# bao1x register map
Vendor: baochip; File version: 1.0
Registers are 32-bit, read-write, reset 0x0 unless marked. A register's access mark holds for its fields unless they carry their own. Offsets are from the block's base; [hi:lo] are bit positions; {n}, {i} and the like mark numbered series.

## IRQARRAY2
Base 0xE0010000
0x00 EV_SOFT — Software interrupt trigger register. ) Bits set to `1` will trigger an interrupt. Interrupts trigger on write, but the value will persist in the register, allowing software to determine if a software interrupt was triggered by reading back the register. Software is responsible for clearing the register to 0. Repeated `1` writes without clearing will still trigger an interrupt.
  [15:0] trigger
0x04 EV_EDGE_TRIGGERED — If a bit is set to 1, then the hardware trigger is edge-triggered
  [15:0] use_edge
0x08 EV_POLARITY — If a bit is set to 1, then the polarity is rising edge triggered; 0 is falling edge triggered. Bit is ignored if `edge_triggered` is 0.
  [15:0] rising
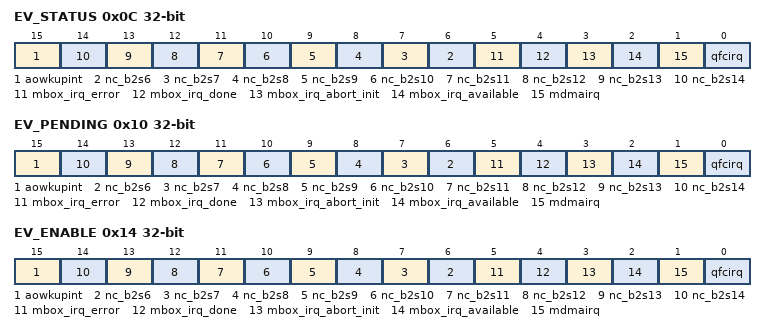
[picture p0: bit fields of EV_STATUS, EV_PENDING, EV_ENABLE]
0x0C EV_STATUS — `1` when a "aowkupint" event occurs. This event uses an `EventSourceFlex` form of triggering
  [15] aowkupint — Level of the ``aowkupint`` event
  [n] nc_b2s{n} (n=6..14) — Level of the ``nc_b2s{n}`` event
  [5] mbox_irq_error — Level of the ``mbox_irq_error`` event
  [4] mbox_irq_done — Level of the ``mbox_irq_done`` event
  [3] mbox_irq_abort_init — Level of the ``mbox_irq_abort_init`` event
  [2] mbox_irq_available — Level of the ``mbox_irq_available`` event
  [1] mdmairq — Level of the ``mdmairq`` event
  [0] qfcirq — Level of the ``qfcirq`` event
0x10 EV_PENDING — `1` when a "aowkupint" event occurs. This event uses an `EventSourceFlex` form of triggering
  [15] aowkupint — `1` when a "aowkupint" event occurs. This event uses an `EventSourceFlex` form of triggering
  [n] nc_b2s{n} (n=6..14) — `1` when a "nc_b2s{n}" event occurs. This event uses an `EventSourceFlex` form of triggering
  [5] mbox_irq_error — `1` when a "mbox_irq_error" event occurs. This event uses an `EventSourceFlex` form of triggering
  [4] mbox_irq_done — `1` when a "mbox_irq_done" event occurs. This event uses an `EventSourceFlex` form of triggering
  [3] mbox_irq_abort_init — `1` when a "mbox_irq_abort_init" event occurs. This event uses an `EventSourceFlex` form of triggering
  [2] mbox_irq_available — `1` when a "mbox_irq_available" event occurs. This event uses an `EventSourceFlex` form of triggering
  [1] mdmairq — `1` when a "mdmairq" event occurs. This event uses an `EventSourceFlex` form of triggering
  [0] qfcirq — `1` when a "qfcirq" event occurs. This event uses an `EventSourceFlex` form of triggering
0x14 EV_ENABLE — `1` when a "aowkupint" event occurs. This event uses an `EventSourceFlex` form of triggering
  [15] aowkupint — Write a ``1`` to enable the ``aowkupint`` Event
  [n] nc_b2s{n} (n=6..14) — Write a ``1`` to enable the ``nc_b2s{n}`` Event
  [5] mbox_irq_error — Write a ``1`` to enable the ``mbox_irq_error`` Event
  [4] mbox_irq_done — Write a ``1`` to enable the ``mbox_irq_done`` Event
  [3] mbox_irq_abort_init — Write a ``1`` to enable the ``mbox_irq_abort_init`` Event
  [2] mbox_irq_available — Write a ``1`` to enable the ``mbox_irq_available`` Event
  [1] mdmairq — Write a ``1`` to enable the ``mdmairq`` Event
  [0] qfcirq — Write a ``1`` to enable the ``qfcirq`` Event

## IRQARRAY3
Base 0xE0011000
0x00 EV_SOFT — Software interrupt trigger register. ) Bits set to `1` will trigger an interrupt. Interrupts trigger on write, but the value will persist in the register, allowing software to determine if a software interrupt was triggered by reading back the register. Software is responsible for clearing the register to 0. Repeated `1` writes without clearing will still trigger an interrupt.
  [15:0] trigger
0x04 EV_EDGE_TRIGGERED — If a bit is set to 1, then the hardware trigger is edge-triggered
  [15:0] use_edge
0x08 EV_POLARITY — If a bit is set to 1, then the polarity is rising edge triggered; 0 is falling edge triggered. Bit is ignored if `edge_triggered` is 0.
  [15:0] rising
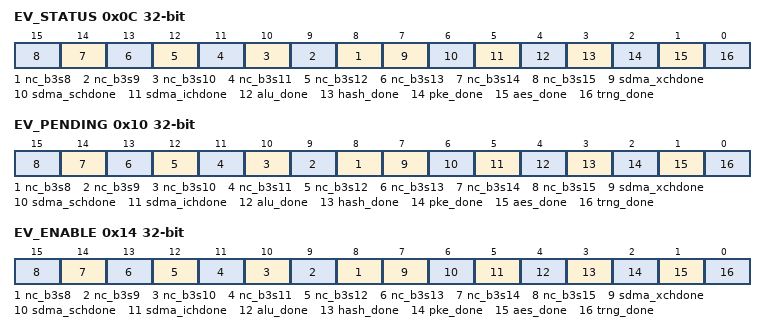
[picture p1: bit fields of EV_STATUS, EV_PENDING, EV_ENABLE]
0x0C EV_STATUS — `1` when a "nc_b3s15" event occurs. This event uses an `EventSourceFlex` form of triggering
  [n] nc_b3s{n} (n=8..15) — Level of the ``nc_b3s{n}`` event
  [7] sdma_xchdone — Level of the ``sdma_xchdone`` event
  [6] sdma_schdone — Level of the ``sdma_schdone`` event
  [5] sdma_ichdone — Level of the ``sdma_ichdone`` event
  [4] alu_done — Level of the ``alu_done`` event
  [3] hash_done — Level of the ``hash_done`` event
  [2] pke_done — Level of the ``pke_done`` event
  [1] aes_done — Level of the ``aes_done`` event
  [0] trng_done — Level of the ``trng_done`` event
0x10 EV_PENDING — `1` when a "nc_b3s15" event occurs. This event uses an `EventSourceFlex` form of triggering
  [n] nc_b3s{n} (n=8..15) — `1` when a "nc_b3s{n}" event occurs. This event uses an `EventSourceFlex` form of triggering
  [7] sdma_xchdone — `1` when a "sdma_xchdone" event occurs. This event uses an `EventSourceFlex` form of triggering
  [6] sdma_schdone — `1` when a "sdma_schdone" event occurs. This event uses an `EventSourceFlex` form of triggering
  [5] sdma_ichdone — `1` when a "sdma_ichdone" event occurs. This event uses an `EventSourceFlex` form of triggering
  [4] alu_done — `1` when a "alu_done" event occurs. This event uses an `EventSourceFlex` form of triggering
  [3] hash_done — `1` when a "hash_done" event occurs. This event uses an `EventSourceFlex` form of triggering
  [2] pke_done — `1` when a "pke_done" event occurs. This event uses an `EventSourceFlex` form of triggering
  [1] aes_done — `1` when a "aes_done" event occurs. This event uses an `EventSourceFlex` form of triggering
  [0] trng_done — `1` when a "trng_done" event occurs. This event uses an `EventSourceFlex` form of triggering
0x14 EV_ENABLE — `1` when a "nc_b3s15" event occurs. This event uses an `EventSourceFlex` form of triggering
  [n] nc_b3s{n} (n=8..15) — Write a ``1`` to enable the ``nc_b3s{n}`` Event
  [7] sdma_xchdone — Write a ``1`` to enable the ``sdma_xchdone`` Event
  [6] sdma_schdone — Write a ``1`` to enable the ``sdma_schdone`` Event
  [5] sdma_ichdone — Write a ``1`` to enable the ``sdma_ichdone`` Event
  [4] alu_done — Write a ``1`` to enable the ``alu_done`` Event
  [3] hash_done — Write a ``1`` to enable the ``hash_done`` Event
  [2] pke_done — Write a ``1`` to enable the ``pke_done`` Event
  [1] aes_done — Write a ``1`` to enable the ``aes_done`` Event
  [0] trng_done — Write a ``1`` to enable the ``trng_done`` Event
